# ioam3358 register map
Registers are 32-bit, access not given, no defined reset value unless marked. A register's access mark holds for its fields unless they carry their own. Addresses are absolute; registers are grouped by the start of their names; [hi:lo] are bit positions.

## EPWM1
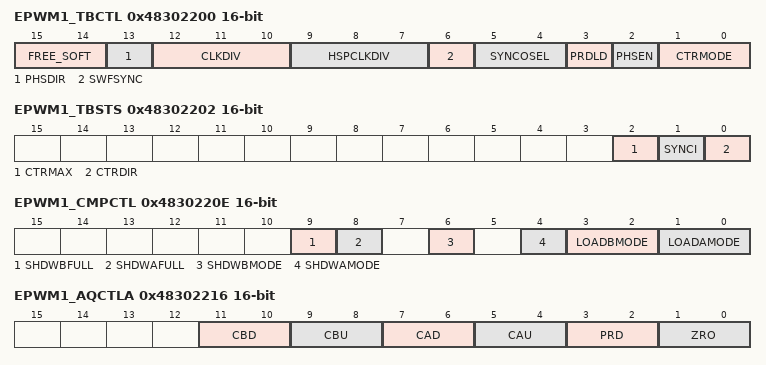
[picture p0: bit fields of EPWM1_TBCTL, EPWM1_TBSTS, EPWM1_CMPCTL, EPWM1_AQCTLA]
0x48302200 EPWM1_TBCTL 16-bit
  [15:14] FREE_SOFT, [13] PHSDIR, [12:10] CLKDIV, [9:7] HSPCLKDIV, [6] SWFSYNC, [5:4] SYNCOSEL, [3] PRDLD, [2] PHSEN, [1:0] CTRMODE
0x48302202 EPWM1_TBSTS 16-bit
  [2] CTRMAX, [1] SYNCI, [0] CTRDIR
0x48302204 EPWM1_TBPHSHR 16-bit
  [15:8] TBPHSH
0x48302206 EPWM1_TBPHS 16-bit
0x48302208 EPWM1_TBCNT 16-bit
0x4830220A EPWM1_TBPRD 16-bit
0x4830220E EPWM1_CMPCTL 16-bit
  [9] SHDWBFULL, [8] SHDWAFULL, [6] SHDWBMODE, [4] SHDWAMODE, [3:2] LOADBMODE, [1:0] LOADAMODE
0x48302210 EPWM1_CMPAHR 16-bit
  [15:8] CMPAHR
0x48302212 EPWM1_CMPA 16-bit
0x48302214 EPWM1_CMPB 16-bit
0x48302216 EPWM1_AQCTLA 16-bit
  [11:10] CBD, [9:8] CBU, [7:6] CAD, [5:4] CAU, [3:2] PRD, [1:0] ZRO
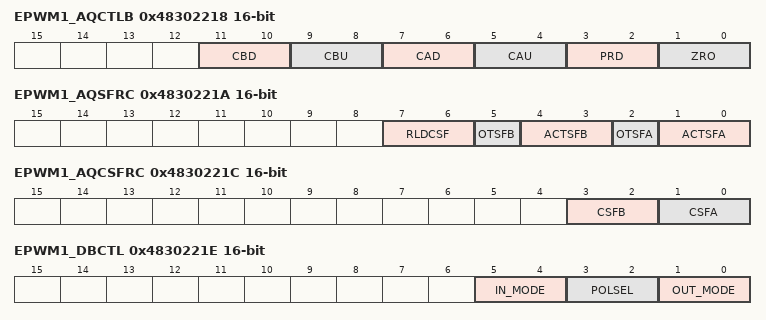
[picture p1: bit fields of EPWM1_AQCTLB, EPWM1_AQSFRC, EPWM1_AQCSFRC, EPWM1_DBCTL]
0x48302218 EPWM1_AQCTLB 16-bit
  [11:10] CBD, [9:8] CBU, [7:6] CAD, [5:4] CAU, [3:2] PRD, [1:0] ZRO
0x4830221A EPWM1_AQSFRC 16-bit
  [7:6] RLDCSF, [5] OTSFB, [4:3] ACTSFB, [2] OTSFA, [1:0] ACTSFA
0x4830221C EPWM1_AQCSFRC 16-bit
  [3:2] CSFB, [1:0] CSFA
0x4830221E EPWM1_DBCTL 16-bit
  [5:4] IN_MODE, [3:2] POLSEL, [1:0] OUT_MODE
0x48302220 EPWM1_DBRED 16-bit
  [9:0] DEL
0x48302222 EPWM1_DBFED 16-bit
  [9:0] DEL
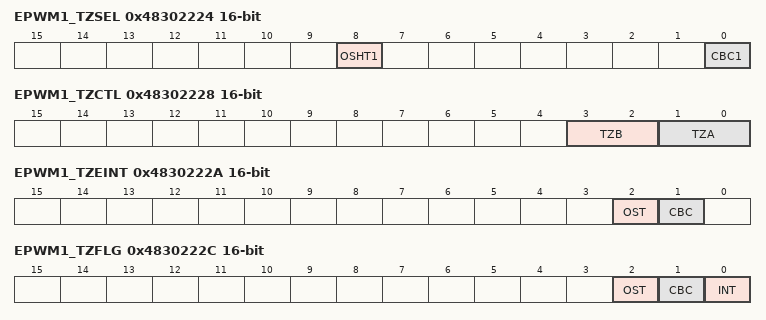
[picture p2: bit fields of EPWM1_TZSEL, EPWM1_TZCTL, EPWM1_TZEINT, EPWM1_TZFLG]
0x48302224 EPWM1_TZSEL 16-bit
  [8] OSHT1, [0] CBC1
0x48302228 EPWM1_TZCTL 16-bit
  [3:2] TZB, [1:0] TZA
0x4830222A EPWM1_TZEINT 16-bit
  [2] OST, [1] CBC
0x4830222C EPWM1_TZFLG 16-bit
  [2] OST, [1] CBC, [0] INT
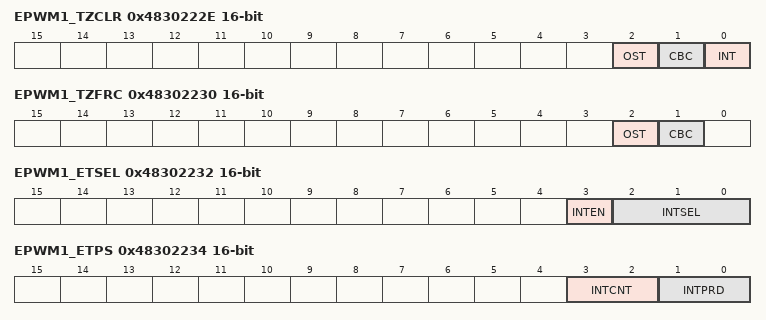
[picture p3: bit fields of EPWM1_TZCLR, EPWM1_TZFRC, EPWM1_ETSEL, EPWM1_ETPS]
0x4830222E EPWM1_TZCLR 16-bit
  [2] OST, [1] CBC, [0] INT
0x48302230 EPWM1_TZFRC 16-bit
  [2] OST, [1] CBC
0x48302232 EPWM1_ETSEL 16-bit
  [3] INTEN, [2:0] INTSEL
0x48302234 EPWM1_ETPS 16-bit
  [3:2] INTCNT, [1:0] INTPRD
0x48302236 EPWM1_ETFLG 16-bit
  [0] INT
0x48302238 EPWM1_ETCLR 16-bit
  [0] INT
0x4830223A EPWM1_ETFRC 16-bit
  [0] INT
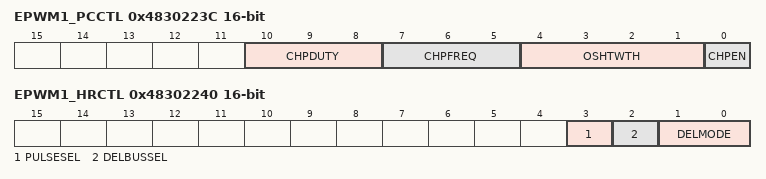
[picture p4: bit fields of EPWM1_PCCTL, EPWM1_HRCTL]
0x4830223C EPWM1_PCCTL 16-bit
  [10:8] CHPDUTY, [7:5] CHPFREQ, [4:1] OSHTWTH, [0] CHPEN
0x48302240 EPWM1_HRCTL 16-bit
  [3] PULSESEL, [2] DELBUSSEL, [1:0] DELMODE

## EPWM2
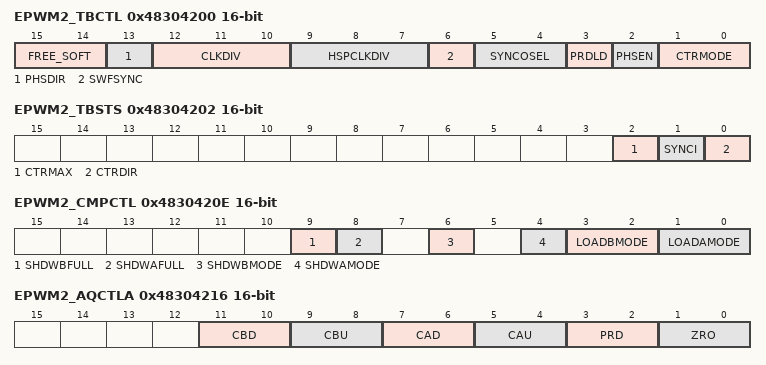
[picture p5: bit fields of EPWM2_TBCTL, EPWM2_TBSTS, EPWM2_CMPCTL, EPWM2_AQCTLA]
0x48304200 EPWM2_TBCTL 16-bit
  [15:14] FREE_SOFT, [13] PHSDIR, [12:10] CLKDIV, [9:7] HSPCLKDIV, [6] SWFSYNC, [5:4] SYNCOSEL, [3] PRDLD, [2] PHSEN, [1:0] CTRMODE
0x48304202 EPWM2_TBSTS 16-bit
  [2] CTRMAX, [1] SYNCI, [0] CTRDIR
0x48304204 EPWM2_TBPHSHR 16-bit
  [15:8] TBPHSH
0x48304206 EPWM2_TBPHS 16-bit
0x48304208 EPWM2_TBCNT 16-bit
0x4830420A EPWM2_TBPRD 16-bit
0x4830420E EPWM2_CMPCTL 16-bit
  [9] SHDWBFULL, [8] SHDWAFULL, [6] SHDWBMODE, [4] SHDWAMODE, [3:2] LOADBMODE, [1:0] LOADAMODE
0x48304210 EPWM2_CMPAHR 16-bit
  [15:8] CMPAHR
0x48304212 EPWM2_CMPA 16-bit
0x48304214 EPWM2_CMPB 16-bit
0x48304216 EPWM2_AQCTLA 16-bit
  [11:10] CBD, [9:8] CBU, [7:6] CAD, [5:4] CAU, [3:2] PRD, [1:0] ZRO
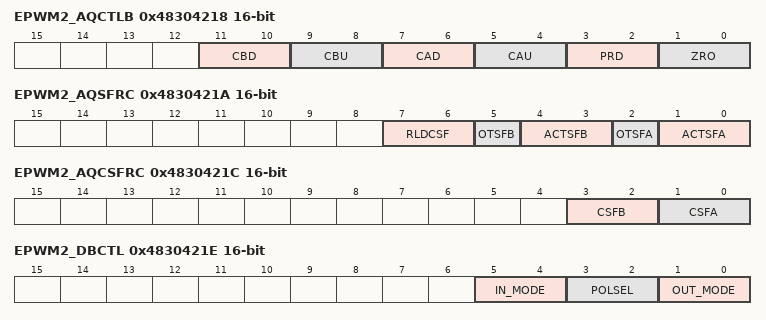
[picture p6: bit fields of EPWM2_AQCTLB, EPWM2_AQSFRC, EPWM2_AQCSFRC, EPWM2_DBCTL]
0x48304218 EPWM2_AQCTLB 16-bit
  [11:10] CBD, [9:8] CBU, [7:6] CAD, [5:4] CAU, [3:2] PRD, [1:0] ZRO
0x4830421A EPWM2_AQSFRC 16-bit
  [7:6] RLDCSF, [5] OTSFB, [4:3] ACTSFB, [2] OTSFA, [1:0] ACTSFA
0x4830421C EPWM2_AQCSFRC 16-bit
  [3:2] CSFB, [1:0] CSFA
0x4830421E EPWM2_DBCTL 16-bit
  [5:4] IN_MODE, [3:2] POLSEL, [1:0] OUT_MODE
0x48304220 EPWM2_DBRED 16-bit
  [9:0] DEL
0x48304222 EPWM2_DBFED 16-bit
  [9:0] DEL
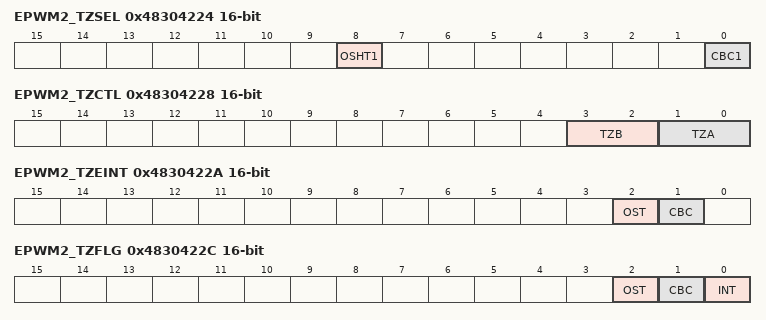
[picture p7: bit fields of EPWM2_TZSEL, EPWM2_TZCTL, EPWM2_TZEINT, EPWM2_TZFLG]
0x48304224 EPWM2_TZSEL 16-bit
  [8] OSHT1, [0] CBC1
0x48304228 EPWM2_TZCTL 16-bit
  [3:2] TZB, [1:0] TZA
0x4830422A EPWM2_TZEINT 16-bit
  [2] OST, [1] CBC
0x4830422C EPWM2_TZFLG 16-bit
  [2] OST, [1] CBC, [0] INT
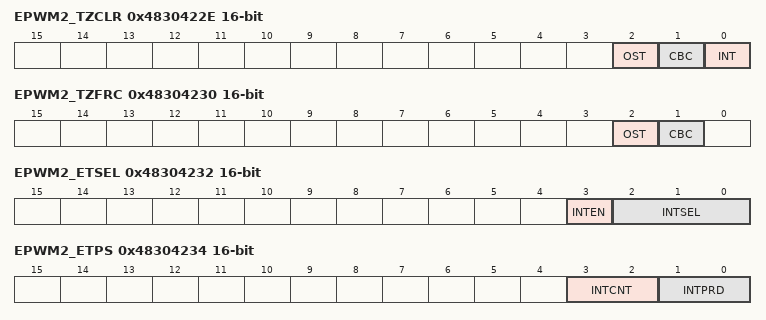
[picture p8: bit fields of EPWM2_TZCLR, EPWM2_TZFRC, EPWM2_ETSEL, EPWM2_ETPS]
0x4830422E EPWM2_TZCLR 16-bit
  [2] OST, [1] CBC, [0] INT
0x48304230 EPWM2_TZFRC 16-bit
  [2] OST, [1] CBC
0x48304232 EPWM2_ETSEL 16-bit
  [3] INTEN, [2:0] INTSEL
0x48304234 EPWM2_ETPS 16-bit
  [3:2] INTCNT, [1:0] INTPRD
0x48304236 EPWM2_ETFLG 16-bit
  [0] INT
0x48304238 EPWM2_ETCLR 16-bit
  [0] INT
0x4830423A EPWM2_ETFRC 16-bit
  [0] INT
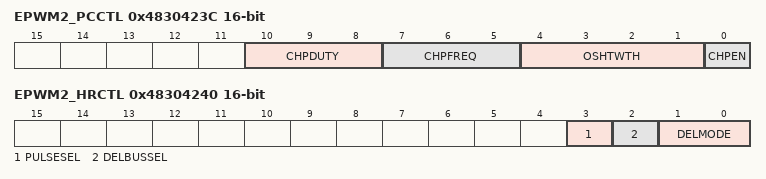
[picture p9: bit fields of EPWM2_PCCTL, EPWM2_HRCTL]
0x4830423C EPWM2_PCCTL 16-bit
  [10:8] CHPDUTY, [7:5] CHPFREQ, [4:1] OSHTWTH, [0] CHPEN
0x48304240 EPWM2_HRCTL 16-bit
  [3] PULSESEL, [2] DELBUSSEL, [1:0] DELMODE
